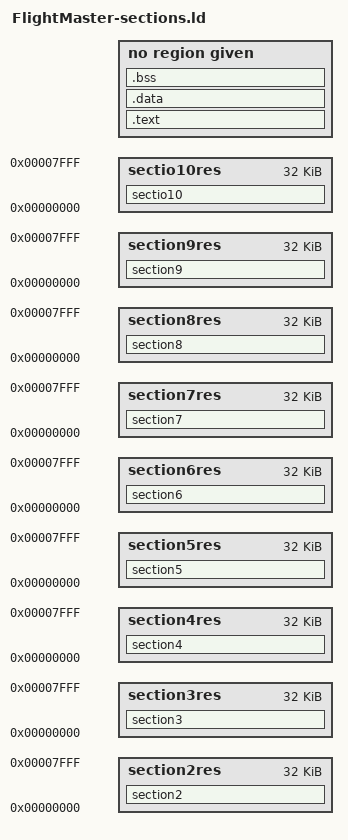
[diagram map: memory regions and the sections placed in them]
/* DO NOT EDIT!
   This file was automatically generated by /usr/bin/m68k-palmos-multigen v2.3
   from FlightMaster.def  */

MEMORY
{
	section2res : ORIGIN = 0x0, LENGTH = 32768
	section3res : ORIGIN = 0x0, LENGTH = 32768
	section4res : ORIGIN = 0x0, LENGTH = 32768
	section5res : ORIGIN = 0x0, LENGTH = 32768
	section6res : ORIGIN = 0x0, LENGTH = 32768
	section7res : ORIGIN = 0x0, LENGTH = 32768
	section8res : ORIGIN = 0x0, LENGTH = 32768
	section9res : ORIGIN = 0x0, LENGTH = 32768
	sectio10res : ORIGIN = 0x0, LENGTH = 32768
}

SECTIONS
{
       /* Section entries for .text, .data and .bss necessary
          to force correct section order in linker output with
          m68k-palmos-ld in prc-tools-2.2 and later */
       .text : { *(.text) } > coderes
       .data : { *(.data) } > datares
       .bss  : { *(.bss)  } > datares
	section2 : { *(section2) } > section2res
	section3 : { *(section3) } > section3res
	section4 : { *(section4) } > section4res
	section5 : { *(section5) } > section5res
	section6 : { *(section6) } > section6res
	section7 : { *(section7) } > section7res
	section8 : { *(section8) } > section8res
	section9 : { *(section9) } > section9res
	sectio10 : { *(sectio10) } > sectio10res
}
